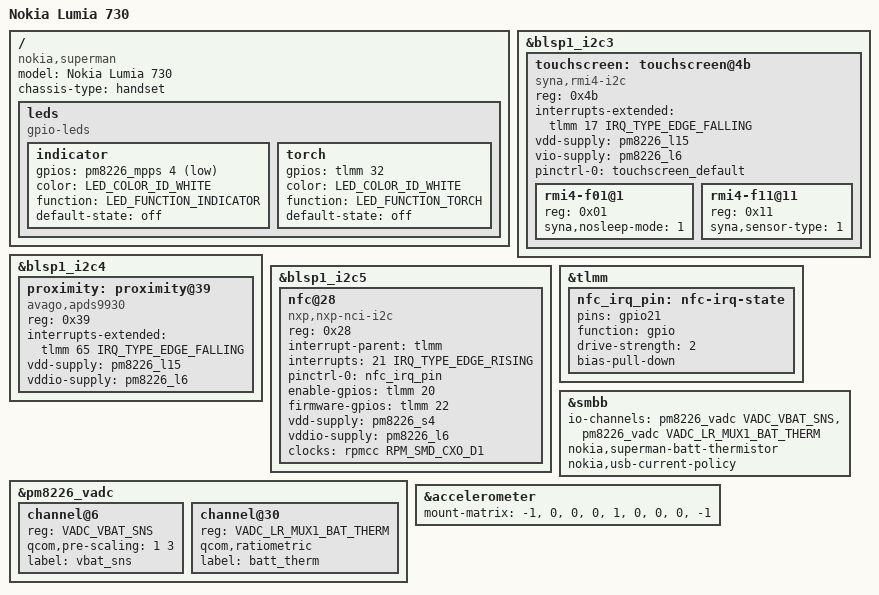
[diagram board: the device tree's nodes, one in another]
// SPDX-License-Identifier: BSD-3-Clause
/*
 * Nokia Lumia 730 (Superman)
 *
 * Based on the Mainline4Lumia Lumia 730 device tree and adapted
 * to the modern qcom-msm8226-microsoft-common.dtsi.
 */

/dts-v1/;

#include "qcom-msm8226.dtsi"
#include "qcom-msm8226-microsoft-common.dtsi"
#include <dt-bindings/clock/qcom,rpmcc.h>
#include <dt-bindings/leds/common.h>

/*
 * The common Microsoft DTS puts the touchscreen on I2C5.
 * Lumia 730 has the touchscreen on I2C3 instead.
 */
/delete-node/ &touchscreen;

/ {
	model = "Nokia Lumia 730";
	compatible = "nokia,superman", "qcom,msm8226";
	chassis-type = "handset";

	leds {
		compatible = "gpio-leds";

		indicator {
			gpios = <&pm8226_mpps 4 GPIO_ACTIVE_LOW>;
			color = <LED_COLOR_ID_WHITE>;
			function = LED_FUNCTION_INDICATOR;
			default-state = "off";
		};

		torch {
			gpios = <&tlmm 32 GPIO_ACTIVE_HIGH>;
			color = <LED_COLOR_ID_WHITE>;
			function = LED_FUNCTION_TORCH;
			default-state = "off";
		};
	};
};

&blsp1_i2c3 {
	status = "okay";

	touchscreen: touchscreen@4b {
		compatible = "syna,rmi4-i2c";
		reg = <0x4b>;

		interrupts-extended = <&tlmm 17 IRQ_TYPE_EDGE_FALLING>;
		vdd-supply = <&pm8226_l15>;
		vio-supply = <&pm8226_l6>;

		pinctrl-0 = <&touchscreen_default>;
		pinctrl-names = "default";

		#address-cells = <1>;
		#size-cells = <0>;

		rmi4-f01@1 {
			reg = <0x01>;
			syna,nosleep-mode = <1>;
		};

		rmi4-f11@11 {
			reg = <0x11>;
			syna,sensor-type = <1>;
		};
	};
};

&blsp1_i2c4 {
	status = "okay";

	proximity: proximity@39 {
		compatible = "avago,apds9930";
		reg = <0x39>;

		interrupts-extended = <&tlmm 65 IRQ_TYPE_EDGE_FALLING>;

		vdd-supply = <&pm8226_l15>;
		vddio-supply = <&pm8226_l6>;
	};
};

&blsp1_i2c5 {
	status = "okay";

	nfc@28 {
		compatible = "nxp,nxp-nci-i2c";
		reg = <0x28>;

		interrupt-parent = <&tlmm>;
		interrupts = <21 IRQ_TYPE_EDGE_RISING>;
		pinctrl-names = "default";
		pinctrl-0 = <&nfc_irq_pin>;

		enable-gpios = <&tlmm 20 GPIO_ACTIVE_HIGH>;
		firmware-gpios = <&tlmm 22 GPIO_ACTIVE_HIGH>;
		vdd-supply = <&pm8226_s4>;
		vddio-supply = <&pm8226_l6>;
		clocks = <&rpmcc RPM_SMD_CXO_D1>;
		clock-names = "bbclk2";
	};
};

&tlmm {
	nfc_irq_pin: nfc-irq-state {
		pins = "gpio21";
		function = "gpio";
		drive-strength = <2>;
		bias-pull-down;
	};
};

/* Measurement only: retain inherited charger current/voltage/thermal limits. */
&pm8226_vadc {
	channel@6 {
		reg = <VADC_VBAT_SNS>;
		qcom,pre-scaling = <1 3>;
		label = "vbat_sns";
	};

	channel@30 {
		reg = <VADC_LR_MUX1_BAT_THERM>;
		qcom,ratiometric;
		label = "batt_therm";
	};
};

&smbb {
	io-channels = <&pm8226_vadc VADC_VBAT_SNS>,
		      <&pm8226_vadc VADC_LR_MUX1_BAT_THERM>;
	io-channel-names = "vbat", "batt-therm";
	nokia,superman-batt-thermistor;
	nokia,usb-current-policy;
};

/* KX022 is rear-mounted; keep Android axes right-handed in portrait. */
&accelerometer {
	mount-matrix = "-1", "0", "0",
		       "0", "1", "0",
		       "0", "0", "-1";
};
